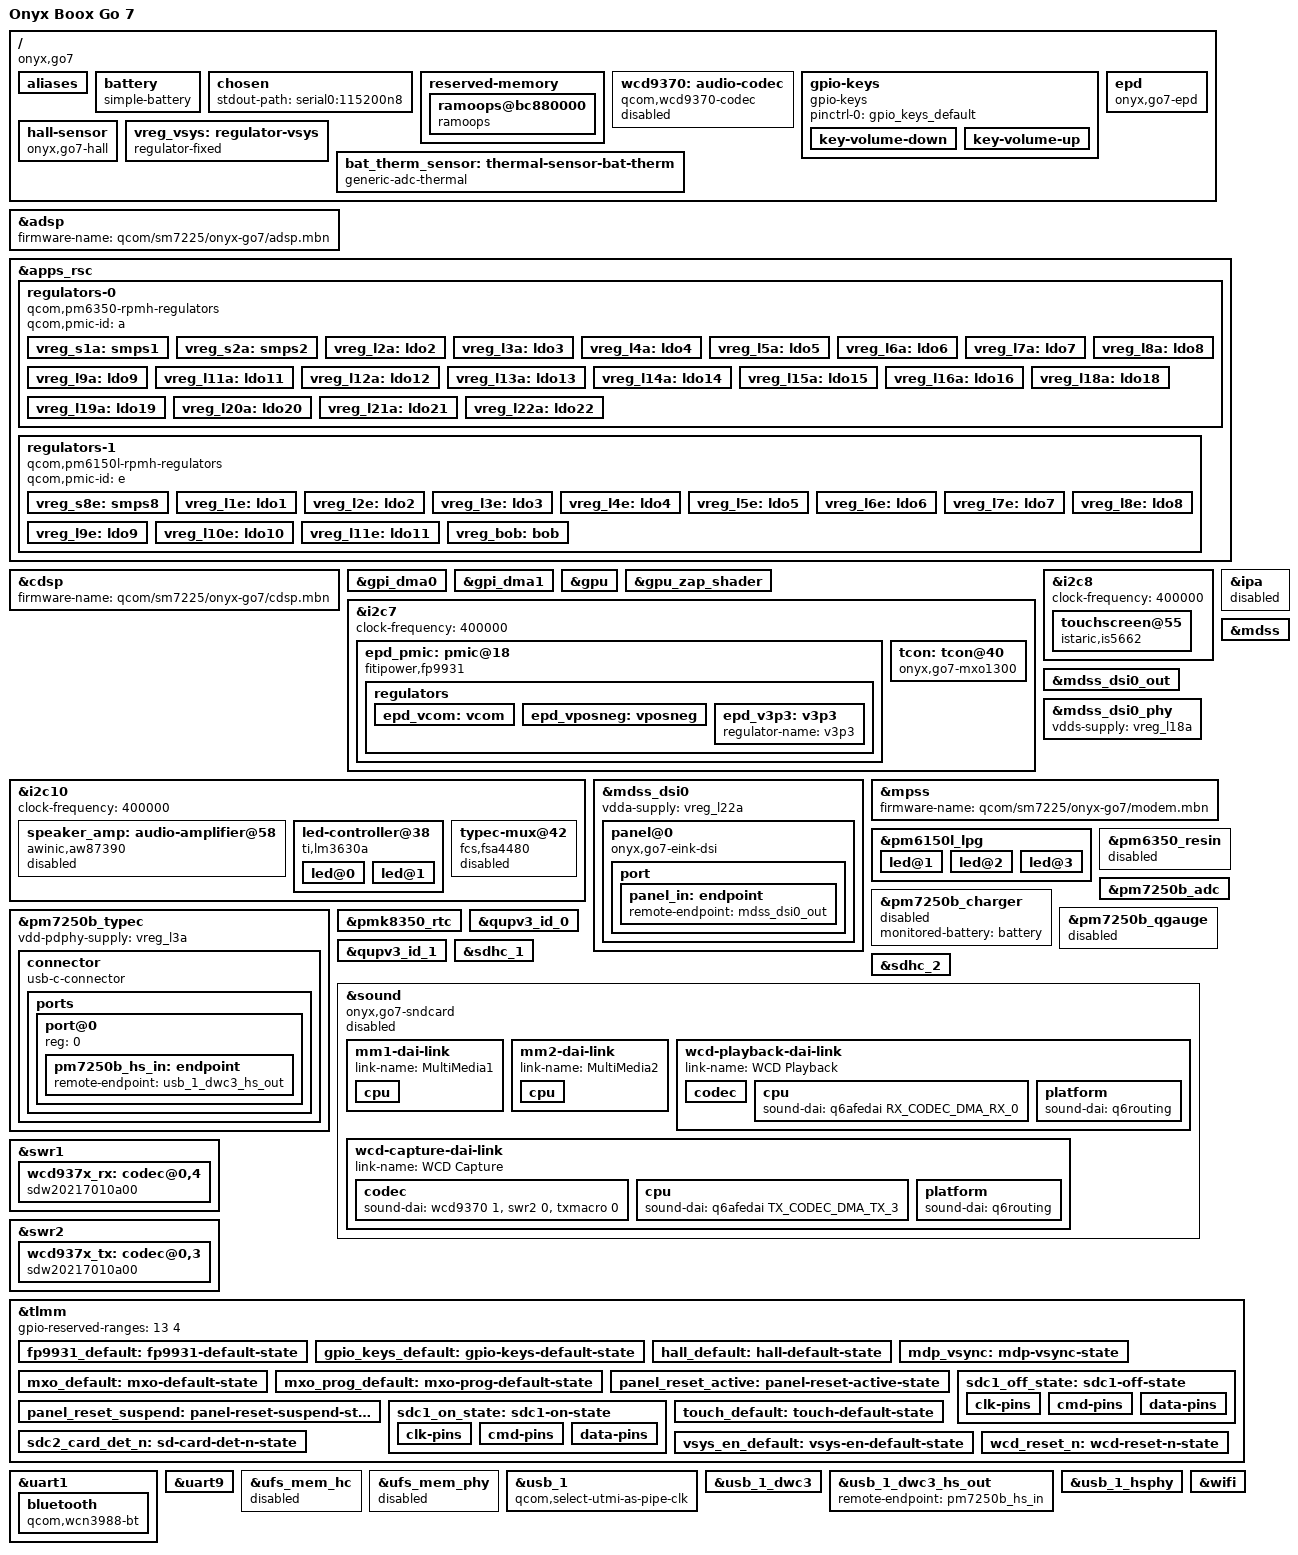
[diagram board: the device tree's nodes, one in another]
// SPDX-License-Identifier: BSD-3-Clause
/*
 * Onyx Boox Go 7 (e-reader, SM7225 "bitra").
 */

/dts-v1/;

#define PM7250B_SID 2
#define PM7250B_SID1 3
#define PMK8350_SID 6

#include <dt-bindings/firmware/qcom,scm.h>
#include <dt-bindings/gpio/gpio.h>
#include <dt-bindings/iio/qcom,spmi-vadc.h>
#include <dt-bindings/input/input.h>
#include <dt-bindings/leds/common.h>
#include <dt-bindings/interrupt-controller/irq.h>
#include <dt-bindings/regulator/qcom,rpmh-regulator.h>
#include <dt-bindings/sound/qcom,q6asm.h>
#include <dt-bindings/usb/pd.h>
#include "sm7225.dtsi"
#include "pm6150l.dtsi"
#include "pm6350.dtsi"
#include "pm7250b.dtsi"
#include "pmk8350.dtsi"

/delete-node/ &ramoops;

/ {
	model = "Onyx Boox Go 7";
	compatible = "onyx,go7", "qcom,sm7225";
	chassis-type = "tablet";

	qcom,msm-id = <434 0x10000>, <459 0x10000>;
	qcom,board-id = <8 0>;

	aliases {
		serial0 = &uart9;
		serial1 = &uart1;
	};

	battery: battery {
		compatible = "simple-battery";
		device-chemistry = "lithium-ion-polymer";
		charge-full-design-microamp-hours = <2339000>;
		constant-charge-current-max-microamp = <1500000>;
		voltage-max-design-microvolt = <4400000>;
		voltage-min-design-microvolt = <3300000>;
		charge-term-current-microamp = <150000>;
	};

	chosen {
		#address-cells = <2>;
		#size-cells = <2>;
		ranges;

		stdout-path = "serial0:115200n8";
	};

	reserved-memory {
		ramoops@bc880000 {
			compatible = "ramoops";
			reg = <0x0 0xbc880000 0x0 0x80000>;
			record-size = <0x20000>;
			console-size = <0x20000>;
			ftrace-size = <0x20000>;
			pmsg-size = <0x20000>;
			no-map;
		};
	};

	wcd9370: audio-codec {
		compatible = "qcom,wcd9370-codec";

		pinctrl-0 = <&wcd_reset_n>;
		pinctrl-names = "default";

		reset-gpios = <&tlmm 83 GPIO_ACTIVE_LOW>;

		vdd-buck-supply = <&vreg_l14a>;
		vdd-rxtx-supply = <&vreg_l11a>;
		vdd-px-supply = <&vreg_l11a>;
		vdd-mic-bias-supply = <&vreg_bob>;

		qcom,micbias1-microvolt = <1800000>;
		qcom,micbias2-microvolt = <1800000>;
		qcom,micbias3-microvolt = <1800000>;
		qcom,micbias4-microvolt = <1800000>;

		qcom,rx-device = <&wcd937x_rx>;
		qcom,tx-device = <&wcd937x_tx>;

		#sound-dai-cells = <1>;

		status = "disabled";
	};

	gpio-keys {
		compatible = "gpio-keys";

		pinctrl-0 = <&gpio_keys_default>;
		pinctrl-names = "default";

		key-volume-down {
			label = "volume_down";
			gpios = <&tlmm 98 GPIO_ACTIVE_LOW>;
			linux,code = <KEY_VOLUMEDOWN>;
			debounce-interval = <15>;
			linux,can-disable;
			wakeup-source;
		};

		key-volume-up {
			label = "volume_up";
			gpios = <&tlmm 144 GPIO_ACTIVE_LOW>;
			linux,code = <KEY_VOLUMEUP>;
			debounce-interval = <15>;
			linux,can-disable;
			wakeup-source;
		};
	};

	epd {
		compatible = "onyx,go7-epd";
		onyx,dsi = <&mdss_dsi0>;
		onyx,tcon = <&tcon>;
		display-supply = <&epd_vposneg>;
		vcom-supply = <&epd_vcom>;
		v3p3-supply = <&epd_v3p3>;
	};

	hall-sensor {
		compatible = "onyx,go7-hall";
		irq-gpios = <&tlmm 99 GPIO_ACTIVE_HIGH>;
		vdd-supply = <&vreg_l11e>;
		onyx,send-alt-key;

		pinctrl-0 = <&hall_default>;
		pinctrl-names = "default";
	};

	vreg_vsys: regulator-vsys {
		compatible = "regulator-fixed";
		regulator-name = "onyx-vsys";
		regulator-min-microvolt = <4000000>;
		regulator-max-microvolt = <4000000>;
		gpio = <&tlmm 33 GPIO_ACTIVE_HIGH>;
		enable-active-high;

		pinctrl-0 = <&vsys_en_default>;
		pinctrl-names = "default";
	};

	bat_therm_sensor: thermal-sensor-bat-therm {
		compatible = "generic-adc-thermal";
		#thermal-sensor-cells = <0>;
		#io-channel-cells = <0>;
		io-channels = <&pm7250b_adc ADC5_BAT_THERM_100K_PU>;
		io-channel-names = "sensor-channel";
		temperature-lookup-table = <
			(-40000) 1840
			(-38000) 1835
			(-36000) 1828
			(-34000) 1821
			(-32000) 1813
			(-30000) 1803
			(-28000) 1793
			(-26000) 1781
			(-24000) 1768
			(-22000) 1753
			(-20000) 1737
			(-18000) 1719
			(-16000) 1700
			(-14000) 1679
			(-12000) 1655
			(-10000) 1630
			 (-8000) 1603
			 (-6000) 1574
			 (-4000) 1543
			 (-2000) 1510
			       0 1475
			    2000 1438
			    4000 1400
			    6000 1360
			    8000 1318
			   10000 1276
			   12000 1232
			   14000 1187
			   16000 1142
			   18000 1097
			   20000 1051
			   22000 1005
			   24000 960
			   26000 915
			   28000 871
			   30000 828
			   32000 786
			   34000 745
			   36000 705
			   38000 666
			   40000 629
			   42000 594
			   44000 560
			   46000 527
			   48000 497
			   50000 467
			   52000 439
			   54000 413
			   56000 388
			   58000 365
			   60000 343
			   62000 322
			   64000 302
			   66000 284
			   68000 267
			   70000 251
			   72000 235
			   74000 221
			   76000 208
			   78000 195
			   80000 184
			   82000 173
			   84000 163
			   86000 153
			   88000 144
			   90000 136
			   92000 128
			   94000 120
			   96000 114
			   98000 107>;
	};
};

&adsp {
	firmware-name = "qcom/sm7225/onyx-go7/adsp.mbn";
	status = "okay";
};

&apps_rsc {
	regulators-0 {
		compatible = "qcom,pm6350-rpmh-regulators";
		qcom,pmic-id = "a";

		vreg_s1a: smps1 {
			regulator-name = "vreg_s1a";
			regulator-min-microvolt = <1000000>;
			regulator-max-microvolt = <1200000>;
		};

		vreg_s2a: smps2 {
			regulator-name = "vreg_s2a";
			regulator-min-microvolt = <1503000>;
			regulator-max-microvolt = <2048000>;
		};

		vreg_l2a: ldo2 {
			regulator-name = "vreg_l2a";
			regulator-min-microvolt = <1503000>;
			regulator-max-microvolt = <1980000>;
			regulator-initial-mode = <RPMH_REGULATOR_MODE_HPM>;
		};

		vreg_l3a: ldo3 {
			regulator-name = "vreg_l3a";
			regulator-min-microvolt = <2700000>;
			regulator-max-microvolt = <3300000>;
			regulator-initial-mode = <RPMH_REGULATOR_MODE_HPM>;
		};

		vreg_l4a: ldo4 {
			regulator-name = "vreg_l4a";
			regulator-min-microvolt = <352000>;
			regulator-max-microvolt = <801000>;
			regulator-initial-mode = <RPMH_REGULATOR_MODE_HPM>;
		};

		vreg_l5a: ldo5 {
			regulator-name = "vreg_l5a";
			regulator-min-microvolt = <1503000>;
			regulator-max-microvolt = <1980000>;
			regulator-initial-mode = <RPMH_REGULATOR_MODE_HPM>;
		};

		vreg_l6a: ldo6 {
			regulator-name = "vreg_l6a";
			regulator-min-microvolt = <1710000>;
			regulator-max-microvolt = <3544000>;
			regulator-initial-mode = <RPMH_REGULATOR_MODE_HPM>;
		};

		vreg_l7a: ldo7 {
			regulator-name = "vreg_l7a";
			regulator-min-microvolt = <1620000>;
			regulator-max-microvolt = <1980000>;
			regulator-initial-mode = <RPMH_REGULATOR_MODE_HPM>;
		};

		vreg_l8a: ldo8 {
			regulator-name = "vreg_l8a";
			regulator-min-microvolt = <2500000>;
			regulator-max-microvolt = <3544000>;
			regulator-initial-mode = <RPMH_REGULATOR_MODE_HPM>;
		};

		vreg_l9a: ldo9 {
			regulator-name = "vreg_l9a";
			regulator-min-microvolt = <1650000>;
			regulator-max-microvolt = <3401000>;
			regulator-initial-mode = <RPMH_REGULATOR_MODE_HPM>;
		};

		vreg_l11a: ldo11 {
			regulator-name = "vreg_l11a";
			regulator-min-microvolt = <1800000>;
			regulator-max-microvolt = <2000000>;
			regulator-initial-mode = <RPMH_REGULATOR_MODE_HPM>;
		};

		vreg_l12a: ldo12 {
			regulator-name = "vreg_l12a";
			regulator-min-microvolt = <1620000>;
			regulator-max-microvolt = <1980000>;
			regulator-initial-mode = <RPMH_REGULATOR_MODE_HPM>;
		};

		vreg_l13a: ldo13 {
			regulator-name = "vreg_l13a";
			regulator-min-microvolt = <570000>;
			regulator-max-microvolt = <650000>;
			regulator-initial-mode = <RPMH_REGULATOR_MODE_HPM>;
		};

		vreg_l14a: ldo14 {
			regulator-name = "vreg_l14a";
			regulator-min-microvolt = <1700000>;
			regulator-max-microvolt = <1900000>;
			regulator-initial-mode = <RPMH_REGULATOR_MODE_HPM>;
		};

		vreg_l15a: ldo15 {
			regulator-name = "vreg_l15a";
			regulator-min-microvolt = <1100000>;
			regulator-max-microvolt = <1305000>;
			regulator-initial-mode = <RPMH_REGULATOR_MODE_HPM>;
		};

		vreg_l16a: ldo16 {
			regulator-name = "vreg_l16a";
			regulator-min-microvolt = <830000>;
			regulator-max-microvolt = <921000>;
			regulator-initial-mode = <RPMH_REGULATOR_MODE_HPM>;
		};

		vreg_l18a: ldo18 {
			regulator-name = "vreg_l18a";
			regulator-min-microvolt = <788000>;
			regulator-max-microvolt = <1049000>;
			regulator-initial-mode = <RPMH_REGULATOR_MODE_HPM>;
		};

		vreg_l19a: ldo19 {
			regulator-name = "vreg_l19a";
			regulator-min-microvolt = <1080000>;
			regulator-max-microvolt = <1305000>;
			regulator-initial-mode = <RPMH_REGULATOR_MODE_HPM>;
		};

		vreg_l20a: ldo20 {
			regulator-name = "vreg_l20a";
			regulator-min-microvolt = <530000>;
			regulator-max-microvolt = <801000>;
			regulator-initial-mode = <RPMH_REGULATOR_MODE_HPM>;
		};

		vreg_l21a: ldo21 {
			regulator-name = "vreg_l21a";
			regulator-min-microvolt = <751000>;
			regulator-max-microvolt = <825000>;
			regulator-initial-mode = <RPMH_REGULATOR_MODE_HPM>;
		};

		vreg_l22a: ldo22 {
			regulator-name = "vreg_l22a";
			regulator-min-microvolt = <1080000>;
			regulator-max-microvolt = <1305000>;
			regulator-initial-mode = <RPMH_REGULATOR_MODE_HPM>;
		};
	};

	regulators-1 {
		compatible = "qcom,pm6150l-rpmh-regulators";
		qcom,pmic-id = "e";

		vreg_s8e: smps8 {
			regulator-name = "vreg_s8e";
			regulator-min-microvolt = <313000>;
			regulator-max-microvolt = <1395000>;
		};

		vreg_l1e: ldo1 {
			regulator-name = "vreg_l1e";
			regulator-min-microvolt = <1620000>;
			regulator-max-microvolt = <1980000>;
			regulator-initial-mode = <RPMH_REGULATOR_MODE_HPM>;
		};

		vreg_l2e: ldo2 {
			regulator-name = "vreg_l2e";
			regulator-min-microvolt = <1170000>;
			regulator-max-microvolt = <1305000>;
			regulator-initial-mode = <RPMH_REGULATOR_MODE_HPM>;
		};

		vreg_l3e: ldo3 {
			regulator-name = "vreg_l3e";
			regulator-min-microvolt = <1100000>;
			regulator-max-microvolt = <1299000>;
			regulator-initial-mode = <RPMH_REGULATOR_MODE_HPM>;
		};

		vreg_l4e: ldo4 {
			regulator-name = "vreg_l4e";
			regulator-min-microvolt = <1620000>;
			regulator-max-microvolt = <3300000>;
			regulator-initial-mode = <RPMH_REGULATOR_MODE_HPM>;
		};

		vreg_l5e: ldo5 {
			regulator-name = "vreg_l5e";
			regulator-min-microvolt = <1620000>;
			regulator-max-microvolt = <3300000>;
			regulator-initial-mode = <RPMH_REGULATOR_MODE_HPM>;
		};

		vreg_l6e: ldo6 {
			regulator-name = "vreg_l6e";
			regulator-min-microvolt = <1700000>;
			regulator-max-microvolt = <3544000>;
			regulator-initial-mode = <RPMH_REGULATOR_MODE_HPM>;
		};

		vreg_l7e: ldo7 {
			regulator-name = "vreg_l7e";
			regulator-min-microvolt = <2700000>;
			regulator-max-microvolt = <3544000>;
			regulator-initial-mode = <RPMH_REGULATOR_MODE_HPM>;
		};

		vreg_l8e: ldo8 {
			regulator-name = "vreg_l8e";
			regulator-min-microvolt = <1620000>;
			regulator-max-microvolt = <2000000>;
			regulator-initial-mode = <RPMH_REGULATOR_MODE_HPM>;
		};

		vreg_l9e: ldo9 {
			regulator-name = "vreg_l9e";
			regulator-min-microvolt = <2700000>;
			regulator-max-microvolt = <3544000>;
			regulator-initial-mode = <RPMH_REGULATOR_MODE_HPM>;
		};

		vreg_l10e: ldo10 {
			regulator-name = "vreg_l10e";
			regulator-min-microvolt = <3000000>;
			regulator-max-microvolt = <3401000>;
			regulator-initial-mode = <RPMH_REGULATOR_MODE_HPM>;
		};

		vreg_l11e: ldo11 {
			regulator-name = "vreg_l11e";
			regulator-min-microvolt = <3000000>;
			regulator-max-microvolt = <3401000>;
			regulator-initial-mode = <RPMH_REGULATOR_MODE_HPM>;
		};

		vreg_bob: bob {
			regulator-name = "vreg_bob";
			regulator-min-microvolt = <1620000>;
			regulator-max-microvolt = <5492000>;
			regulator-initial-mode = <RPMH_REGULATOR_MODE_AUTO>;
			regulator-allow-bypass;
		};
	};
};

&cdsp {
	firmware-name = "qcom/sm7225/onyx-go7/cdsp.mbn";
	status = "okay";
};

&gpi_dma0 {
	status = "okay";
};

&gpi_dma1 {
	status = "okay";
};

&gpu {
	status = "okay";
};

&gpu_zap_shader {
	firmware-name = "qcom/sm7225/onyx-go7/a615_zap.mbn";
};

&i2c7 {
	clock-frequency = <400000>;
	status = "okay";

	epd_pmic: pmic@18 {
		compatible = "fitipower,fp9931";
		reg = <0x18>;
		enable-gpios = <&tlmm 139 GPIO_ACTIVE_HIGH>;
		pg-gpios = <&tlmm 53 GPIO_ACTIVE_HIGH>;
		vin-supply = <&vreg_l8a>;

		pinctrl-0 = <&fp9931_default>;
		pinctrl-names = "default";

		regulators {
			epd_vcom: vcom {
				regulator-name = "vcom";
				regulator-min-microvolt = <500000>;
				regulator-max-microvolt = <3000000>;
			};

			epd_vposneg: vposneg {
				regulator-name = "vposneg";
				regulator-min-microvolt = <15060000>;
				regulator-max-microvolt = <15060000>;
			};

			epd_v3p3: v3p3 {
				regulator-name = "v3p3";
			};
		};
	};

	tcon: tcon@40 {
		compatible = "onyx,go7-mxo1300";
		reg = <0x40>;
		reset-gpios = <&tlmm 12 GPIO_ACTIVE_LOW>;
		done-gpios = <&tlmm 155 GPIO_ACTIVE_HIGH>;
		vsys-supply = <&vreg_vsys>;
		vdd1v8-supply = <&vreg_l5a>;
		vdd3v-supply = <&vreg_l8a>;
		vdd1v2-supply = <&vreg_l3e>;

		pinctrl-0 = <&mxo_default>, <&mxo_prog_default>;
		pinctrl-names = "default";
	};
};

&i2c8 {
	clock-frequency = <400000>;
	status = "okay";

	touchscreen@55 {
		compatible = "istaric,is5662";
		reg = <0x55>;
		interrupts-extended = <&tlmm 22 IRQ_TYPE_LEVEL_LOW>;
		reset-gpios = <&tlmm 21 GPIO_ACTIVE_LOW>;
		vdd-enable-gpios = <&tlmm 88 GPIO_ACTIVE_HIGH>;
		vcc-enable-gpios = <&tlmm 89 GPIO_ACTIVE_HIGH>;
		vdd-supply = <&vreg_l5a>;
		vcc-supply = <&vreg_l6a>;
		touchscreen-size-x = <1264>;
		touchscreen-size-y = <1680>;

		pinctrl-0 = <&touch_default>;
		pinctrl-names = "default";
	};
};

&i2c10 {
	clock-frequency = <400000>;
	status = "okay";

	speaker_amp: audio-amplifier@58 {
		compatible = "awinic,aw87390";
		reg = <0x58>;
		#sound-dai-cells = <0>;
		awinic,audio-channel = <0>;
		sound-name-prefix = "Speaker";
		status = "disabled";
	};

	led-controller@38 {
		compatible = "ti,lm3630a";
		reg = <0x38>;
		enable-gpios = <&tlmm 73 GPIO_ACTIVE_HIGH>;
		#address-cells = <1>;
		#size-cells = <0>;

		led@0 {
			reg = <0>;
			led-sources = <0>;
			label = "frontlight-white";
			default-brightness = <0>;
			max-brightness = <255>;
		};

		led@1 {
			reg = <1>;
			led-sources = <1>;
			label = "frontlight-warm";
			default-brightness = <0>;
			max-brightness = <255>;
		};
	};

	typec-mux@42 {
		compatible = "fcs,fsa4480";
		reg = <0x42>;
		vcc-supply = <&vreg_l5a>;
		mode-switch;
		orientation-switch;
		status = "disabled";
	};
};

&ipa {
	qcom,gsi-loader = "self";
	memory-region = <&pil_ipa_fw_mem>;
	firmware-name = "qcom/sm7225/onyx-go7/ipa_fws.mbn";
	status = "disabled";
};

&mdss {
	status = "okay";
};

&mdss_dsi0 {
	vdda-supply = <&vreg_l22a>;
	status = "okay";

	panel@0 {
		compatible = "onyx,go7-eink-dsi";
		reg = <0>;
		reset-gpios = <&tlmm 51 GPIO_ACTIVE_LOW>;

		pinctrl-0 = <&panel_reset_active>, <&mdp_vsync>;
		pinctrl-1 = <&panel_reset_suspend>, <&mdp_vsync>;
		pinctrl-names = "default", "sleep";

		port {
			panel_in: endpoint {
				remote-endpoint = <&mdss_dsi0_out>;
			};
		};
	};
};

&mdss_dsi0_out {
	data-lanes = <0 1>;
	qcom,te-source = "none";
	remote-endpoint = <&panel_in>;
};

&mdss_dsi0_phy {
	vdds-supply = <&vreg_l18a>;
	status = "okay";
};

&mpss {
	firmware-name = "qcom/sm7225/onyx-go7/modem.mbn";
	status = "okay";
};

&pm6150l_lpg {
	status = "okay";

	led@1 {
		reg = <1>;
		color = <LED_COLOR_ID_RED>;
		function = LED_FUNCTION_STATUS;
	};

	led@2 {
		reg = <2>;
		color = <LED_COLOR_ID_GREEN>;
		function = LED_FUNCTION_STATUS;
	};

	led@3 {
		reg = <3>;
		color = <LED_COLOR_ID_BLUE>;
		function = LED_FUNCTION_STATUS;
		linux,default-trigger = "heartbeat";
	};
};

&pm6350_resin {
	status = "disabled";
};

&pm7250b_adc {
	status = "okay";
};

&pm7250b_charger {
	monitored-battery = <&battery>;
	status = "disabled";
};

&pm7250b_qgauge {
	monitored-battery = <&battery>;
	io-channels = <&bat_therm_sensor>,
		      <&pm7250b_adc ADC5_BAT_ID_100K_PU>;
	status = "disabled";
};

&pm7250b_typec {
	vdd-pdphy-supply = <&vreg_l3a>;
	status = "okay";

	connector {
		compatible = "usb-c-connector";

		power-role = "sink";
		data-role = "device";
		self-powered;

		typec-power-opmode = "default";
		pd-disable;

		ports {
			#address-cells = <1>;
			#size-cells = <0>;

			port@0 {
				reg = <0>;
				pm7250b_hs_in: endpoint {
					remote-endpoint = <&usb_1_dwc3_hs_out>;
				};
			};
		};
	};
};

&pmk8350_rtc {
	status = "okay";
};

&qupv3_id_0 {
	status = "okay";
};

&qupv3_id_1 {
	status = "okay";
};

&sdhc_1 {
	vmmc-supply = <&vreg_l7e>;
	vqmmc-supply = <&vreg_l12a>;

	pinctrl-0 = <&sdc1_on_state>;
	pinctrl-1 = <&sdc1_off_state>;
	pinctrl-names = "default", "sleep";

	bus-width = <8>;
	non-removable;
	mmc-ddr-1_8v;
	mmc-hs200-1_8v;
	mmc-hs400-1_8v;
	mmc-hs400-enhanced-strobe;
	supports-cqe;
	no-sd;
	no-sdio;

	status = "okay";
};

&sdhc_2 {
	vmmc-supply = <&vreg_l9e>;
	vqmmc-supply = <&vreg_l6e>;
	cd-gpios = <&tlmm 94 GPIO_ACTIVE_LOW>;

	pinctrl-0 = <&sdc2_on_state>, <&sdc2_card_det_n>;
	pinctrl-1 = <&sdc2_off_state>, <&sdc2_card_det_n>;
	pinctrl-names = "default", "sleep";

	status = "okay";
};

&sound {
	compatible = "onyx,go7-sndcard";
	model = "Onyx Boox Go 7";
	status = "disabled";

	audio-routing = "IN1_HPHL", "HPHL_OUT",
			"IN2_HPHR", "HPHR_OUT",
			"IN3_AUX", "AUX_OUT",
			"Speaker IN", "AUX",
			"AMIC1", "MIC BIAS1",
			"AMIC2", "MIC BIAS2",
			"AMIC3", "MIC BIAS3",
			"TX SWR_ADC0", "ADC1_OUTPUT",
			"TX SWR_ADC2", "ADC2_OUTPUT",
			"TX SWR_ADC3", "ADC3_OUTPUT";

	mm1-dai-link {
		link-name = "MultiMedia1";

		cpu {
			sound-dai = <&q6asmdai MSM_FRONTEND_DAI_MULTIMEDIA1>;
		};
	};

	mm2-dai-link {
		link-name = "MultiMedia2";

		cpu {
			sound-dai = <&q6asmdai MSM_FRONTEND_DAI_MULTIMEDIA2>;
		};
	};

	wcd-playback-dai-link {
		link-name = "WCD Playback";

		codec {
			sound-dai = <&wcd9370 0>, <&swr1 0>, <&rxmacro 0>, <&speaker_amp>;
		};

		cpu {
			sound-dai = <&q6afedai RX_CODEC_DMA_RX_0>;
		};

		platform {
			sound-dai = <&q6routing>;
		};
	};

	wcd-capture-dai-link {
		link-name = "WCD Capture";

		codec {
			sound-dai = <&wcd9370 1>, <&swr2 0>, <&txmacro 0>;
		};

		cpu {
			sound-dai = <&q6afedai TX_CODEC_DMA_TX_3>;
		};

		platform {
			sound-dai = <&q6routing>;
		};
	};
};

&swr1 {
	wcd937x_rx: codec@0,4 {
		compatible = "sdw20217010a00";
		reg = <0 4>;
		qcom,rx-port-mapping = <1 2 3 4 5>;
	};
};

&swr2 {
	wcd937x_tx: codec@0,3 {
		compatible = "sdw20217010a00";
		reg = <0 3>;
		qcom,tx-port-mapping = <1 1 2 3>;
	};
};

&tlmm {
	gpio-reserved-ranges = <13 4>;

	fp9931_default: fp9931-default-state {
		pins = "gpio53", "gpio139";
		function = "gpio";
		drive-strength = <2>;
		bias-disable;
	};

	gpio_keys_default: gpio-keys-default-state {
		pins = "gpio98", "gpio144";
		function = "gpio";
		drive-strength = <2>;
		bias-pull-up;
	};

	hall_default: hall-default-state {
		pins = "gpio99";
		function = "gpio";
		drive-strength = <2>;
		bias-disable;
	};

	mdp_vsync: mdp-vsync-state {
		pins = "gpio23";
		function = "mdp_vsync";
		drive-strength = <2>;
		bias-pull-down;
	};

	mxo_default: mxo-default-state {
		pins = "gpio12";
		function = "gpio";
		drive-strength = <2>;
		bias-disable;
	};

	mxo_prog_default: mxo-prog-default-state {
		pins = "gpio11", "gpio147", "gpio155";
		function = "gpio";
		drive-strength = <2>;
		bias-pull-up;
	};

	panel_reset_active: panel-reset-active-state {
		pins = "gpio51";
		function = "gpio";
		drive-strength = <8>;
		bias-disable;
	};

	panel_reset_suspend: panel-reset-suspend-state {
		pins = "gpio51";
		function = "gpio";
		drive-strength = <2>;
		bias-pull-down;
	};

	sdc1_off_state: sdc1-off-state {
		clk-pins {
			pins = "sdc1_clk";
			drive-strength = <2>;
			bias-disable;
		};

		cmd-pins {
			pins = "sdc1_cmd";
			drive-strength = <2>;
			bias-pull-up;
		};

		data-pins {
			pins = "sdc1_data";
			drive-strength = <2>;
			bias-pull-up;
		};
	};

	sdc1_on_state: sdc1-on-state {
		clk-pins {
			pins = "sdc1_clk";
			drive-strength = <16>;
			bias-disable;
		};

		cmd-pins {
			pins = "sdc1_cmd";
			drive-strength = <10>;
			bias-pull-up;
		};

		data-pins {
			pins = "sdc1_data";
			drive-strength = <10>;
			bias-pull-up;
		};
	};

	sdc2_card_det_n: sd-card-det-n-state {
		pins = "gpio94";
		function = "gpio";
		drive-strength = <2>;
		bias-pull-up;
	};

	touch_default: touch-default-state {
		pins = "gpio21", "gpio22", "gpio88", "gpio89";
		function = "gpio";
		drive-strength = <4>;
		bias-pull-up;
	};

	vsys_en_default: vsys-en-default-state {
		pins = "gpio33";
		function = "gpio";
		drive-strength = <2>;
		bias-disable;
	};

	wcd_reset_n: wcd-reset-n-state {
		pins = "gpio83";
		function = "gpio";
		drive-strength = <16>;
		output-high;
	};
};

&uart1 {
	status = "okay";

	bluetooth {
		compatible = "qcom,wcn3988-bt";

		vddio-supply = <&vreg_l11a>;
		vddxo-supply = <&vreg_l7a>;
		vddrf-supply = <&vreg_l2e>;
		vddch0-supply = <&vreg_l10e>;
		swctrl-gpios = <&tlmm 69 GPIO_ACTIVE_HIGH>;

		max-speed = <3200000>;
	};
};

&uart9 {
	status = "okay";
};

&ufs_mem_hc {
	status = "disabled";
};

&ufs_mem_phy {
	status = "disabled";
};

&usb_1 {
	qcom,select-utmi-as-pipe-clk;

	status = "okay";
};

&usb_1_dwc3 {
	maximum-speed = "high-speed";
	dr_mode = "peripheral";
	phys = <&usb_1_hsphy>;
	phy-names = "usb2-phy";
};

&usb_1_dwc3_hs_out {
	remote-endpoint = <&pm7250b_hs_in>;
};

&usb_1_hsphy {
	vdd-supply = <&vreg_l18a>;
	vdda-pll-supply = <&vreg_l2a>;
	vdda-phy-dpdm-supply = <&vreg_l3a>;

	status = "okay";
};

&wifi {
	vdd-0.8-cx-mx-supply = <&vreg_l4a>;
	vdd-1.8-xo-supply = <&vreg_l7a>;
	vdd-1.3-rfa-supply = <&vreg_l2e>;
	vdd-3.3-ch0-supply = <&vreg_l10e>;
	vdd-3.3-ch1-supply = <&vreg_l11e>;

	status = "okay";
};
